# psoc4100sp register map
Vendor: Cypress Semiconductor; Series: PSoC4100Sp; File version: 1.0
CPU: CM0PLUS r0p1, little endian, no MPU, no FPU, VTOR, 2 interrupt priority bits
Registers are 32-bit, read-write, reset 0x0 unless marked. A register's access mark holds for its fields unless they carry their own. Offsets are from the block's base; [hi:lo] are bit positions; lines under a group give offsets from that group; {n}, {i} and the like mark numbered series.

## DMAC — DataWire/DMA Controller
Base 0x40101000
0x00 CTL — Control register
  [31] ENABLED — 0': IP is disabled. Non-retainable MMIO registers and logic functionality are reset (retainable MMIO registers are NOT reset): - INTR register is set to '0'. - DW/DMA functionality is aborted. - DW/DMA controller input/pending triggers are de-activated. - DW/DMA controller output triggers are de-activated. Disabling the IP has the same effect as an active 'rst_sys_act_n' reset in DeepSleep power mode. To prevent a loss of active (pending) DW/DMA triggers when disabling the IP or when transitioning from Active to DeepSleep power mode, the STATUS.ACTIVE and STATUS_CH_ACTIVE.CH fields can be used. Note that most MMIO registers are retainable, and a transition from DeepSleep to Active/Sleep power modes makes the DW/DMA controller operational, and ready to react to DW/DMA input triggers that are activated after the transition. Triggers are Active/Sleep functionality. '1': IP is enabled.
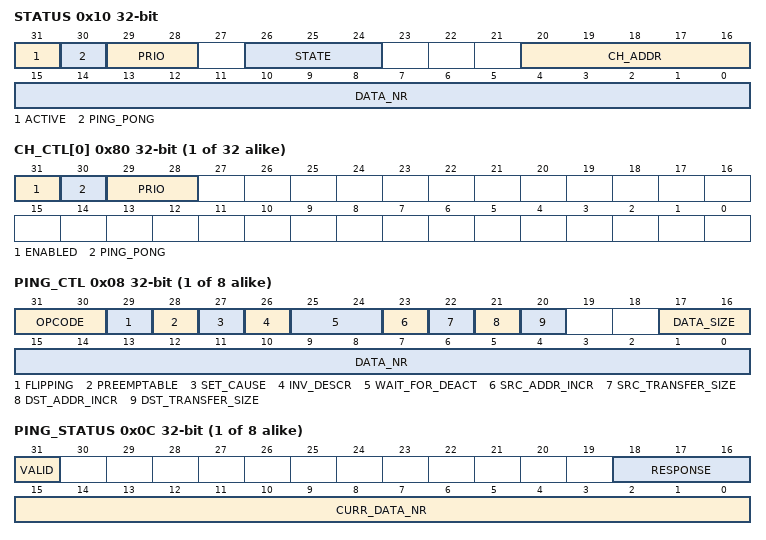
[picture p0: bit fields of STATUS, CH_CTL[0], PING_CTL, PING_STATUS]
0x10 STATUS ro (reset mask 0x87000000)
  [31] ACTIVE — Specifies if there is a currently active (pending) channel in the data transfer engine: '0': no currently active channel. '1': currently active channel.
  [30] PING_PONG — Specifies whether the PING descriptor ('0') or PONG descriptor ('1') of the channel is currently in use.
  [29:28] PRIO — Specifies the priority of the currently active channel.
  [26:24] STATE — State of the data transfer engine. '0': DEFAULT state. '1': Loading descriptor (SRC, DST, CONTROL and STATUS words). '2': Loading data element from source location. '3': Storing data element to destination location. '4': Storing descriptor (STATUS word). '5': Wait for trigger de-activation. '6': Storing descriptor with error response (STATUS word).
  [20:16] CH_ADDR — Specifies the channel number of the currently active channel. E.g. if we have 32 channels, the channel number address with CH_ADDR_WIDTH is LOG2 (32) = 5, and this field is a 5-bit field. If channel 7 is active, STATUS.ACTIVE is '1' and STATUS.CH_ADDR is '7'.
  [15:0] DATA_NR — Specifies the index of the currently active data transfer. This value increases from '0' to CONTROL.DATA_NR.
0x14 STATUS_SRC_ADDR ro reset not defined — Source address status register
  [31:0] ADDR — Base address or current address of source location of currently active channel. The specific address information is cycle dependent. This is field is provided for debug purposes. Functionally, no assumption should be made on whether the base or current address is provided. The specifics of the currently active channel are available through STATUS. Note while reading the STATUS, STATUS_SRC and STATUS_DST registers, the transfer engine may have moved from one active channel to another.
0x18 STATUS_DST_ADDR ro reset not defined — Destination address register
  [31:0] ADDR — Base address or current address of destination location of currently active channel. The specific address information is cycle dependent. This is field is provided for debug purposes. Functionally, no assumption should be made on whether the base or current address is provided. The specifics of the currently active channel are available through STATUS. Note while reading the STATUS, STATUS_SRC and STATUS_DST registers, the transfer engine may have moved from one active channel to another.
0x1C STATUS_CH_ACT ro — Channel activation status register
  [31:0] CH — Channel activation status. Bit i is associated to channel i, with i = 0, ..., CH_NR-1. Software reads this field to get information on all actively pending channels (either in pending or in the data transfer engine).
{0x80+4i} CH_CTL[{i}] (i=0..31) — Channel control register
  [31] ENABLED — '0': channel disabled. The channel's trigger is ignored and the channel cannot be activated. If the activated channel is disabled, the data transfer(s) are aborted. '1': channel enabled. Software sets this field to '1' to enable a specific channel. Hardware sets this field to '0' on erroneous channel behavior (the specific error is specified by STATUS.RESP in the channel's descriptor structure).
  [30] PING_PONG — Each channel has two descriptor structures for double buffering purposes. As the controller operates on one structure, the main CPU can operate on the other structure. The descriptor structures are identified as PING ('0') and PONG ('1'). This field identifies the descriptor structure that is currently in use by the controller. Software sets this field to the desired descriptor structure. Hardware inverts the field value on the completion of a descriptor structure when CONTROL.FLIPPING of the current descriptor structure is set to '1'. Each channel has two descriptor structures for double buffering purposes. As the controller operates on one structure, the main CPU can operate on the other structure. The descriptor structures are identified as PING ('0') and PONG ('1'). This field identifies the descriptor structure that is currently in use by the controller.
  [29:28] PRIO — Channel priority, with '0' representing the highest priority and '3' representing the lowest priority. Priority decoding uses the channel priority to determine the highest priority activated channel. If multiple activated channels have the same highest priority, the channel with the lowest index i, is considered the highest priority activated channel.
0x7F0 INTR — Interrupt register
  [31:0] CH — Set to '1', when event is detected. Write INTR field with '1', to clear bit. Write INTR_SET field with '1', to set bit.
0x7F4 INTR_SET — Interrupt set register
  [31:0] CH — Write INTR_SET field with '1' to set corresponding INTR field (a write of '0' has no effect).
0x7F8 INTR_MASK — Interrupt mask register
  [31:0] CH — Mask for corresponding field in INTR register.
0x7FC INTR_MASKED ro — Interrupt masked register
  [31:0] CH — Logical and of corresponding request and mask fields.
{0x800+0x20*i} DESCR[{i}] (i=0..7) group — Descriptors
  0x00 PING_SRC reset not defined — Ping source address
    [31:0] ADDR — Base address of source location. The effective source location is calculated by adding on offset (derived from PING.STATUS.CURR_DATA_NR) to this base address.
  0x04 PING_DST reset not defined — Ping destination address
    [31:0] ADDR — Base address of destination location. The effective destination location is calculated by adding on offset (derived from PING.STATUS.CURR_DATA_NR) to this base address.
  0x08 PING_CTL reset not defined — Ping control word
    [31:30] OPCODE — Specifies the specific data transfer (only when the VALID bit of the descriptor's STATUS word is '1'): '0': A single trigger initiates a single data element transfer (DW mode). This opcode specifies a transfer of a single data element. The current descriptor is completed when the amount of transferred single data elements equals the programmed buffer size (DATA_NR+1). '1': A single trigger initiates a single descriptor transfer (DMA mode). This opcode specifies a transfer of DATA_NR+1 data elements as specified by the current descriptor structure. The current descriptor is completed when its data transfer is completed. '2': A single trigger initiates a descriptor list transfer (DMA mode). This opcode specifies a transfer of DATA_NR+1 data elements as specified by the current descriptor structure and by successive valid descriptors. The current descriptor is completed when its data transfer is completed. This OPCODE relies on FLIPPING to be set to '1', such that the CHi_CTL.PING_PONG field is flipped/inverted and the successive descriptor is used. This continues for as long as the successive descriptor is valid. Note that as the HW is using the PING/PONG descriptor, the SW can prepare the alternate PONG/PING descriptor. The interrupt mechanism is used by HW to convey to the SW that the current descriptor is completed (and can be prepared for a successive transfer). After completerion of the opcode (and waiting for de-activation, the channel's output trigger is activated).
    [29] FLIPPING — '1': On completion of the current descriptor structure, the current descriptor identifier CHi_CTL.PING_PONG is flipped/inverted. In DMA mode, descriptor list transfer, flipping of the current descriptor identifier can be used to construct a linked list of descriptor structures.
    [28] PREEMPTABLE — '1': Transfer is preemptable. In DMA mode (OPCODE is '1' or '2'), multi data element transfers are constructed out of multiple single data element load (from the source location) and store (to the destination location) sequences. This field allows higher priority activated channels to preempt the current transfer in between these atomic (load, store) sequences. Preemption will NOT deactivate the current channel. As a result, after completion of a higher priority activated channel, the current channel is rescheduled.
    [27] SET_CAUSE — '1': On completion of the current descriptor structure, the interrupt cause field of the channel is set to '1' (INTR.CH[i]).
    [26] INV_DESCR — '1': On completion of the current descriptor structure, the VALID bit of the descriptor's STATUS word is set to '0'.
    [25:24] WAIT_FOR_DEACT — Specifies whether the data transfer engine should wait for the channel to be deactivated; i.e. the selected system trigger is not active. This field is used to synchronize the controller's data transfer(s) with the agent that generated the trigger. This field is ONLY used at the completion of an opcode. E.g., a FIFO indicates that it is empty and it needs a new data sample. The agent removes the trigger ONLY when the data sample has been written by the transfer engine AND received by the agent. Furthermore, the agent's trigger may be delayed by a few cycles before it reaches the DW/DMA controller. This field is used for level sensitive trigger, which reflect state (pulse sensitive triggers should have this field set to '0'). The wait cycles incurred by this field reduce DW/DMA controller performance. '0': Do not wait for de-activation (for pulse sensitive triggers). '1': Wait for up to 4 cycles. '2': Wait for up to 8 cycles. '3': Wait indefinitely. This option may result in DW/DMA controller lockup if the system trigger is not de-activated by the source agent.
    [23] SRC_ADDR_INCR — Specifies whether the source location address is incremented by the SRC_TRANSFER_SIZE after each single data element transfer or not. '0': No increment, typically used for receive (RX) FIFO structures. '1': Increment, typically used for memory structures.
    [22] SRC_TRANSFER_SIZE — Specifies the bus transfer size to the source location: '0': As specified by DATA_SIZE. '1': Word (32 bits). Distinguishing bus transfer size from data element size allows for source components with data elements that are smaller than their 32-bit bus interface width. E.g., an ADC source has a 32-bit bus transfer size, but only provides a 16-bit data element.
    [21] DST_ADDR_INCR — Specifies whether the destination location address is incremented by the DST_TRANSFER_SIZE after each single data element transfer or not. '0' : No increment, typically used for transmit (TX) FIFO structures. '1': Increment, typically used for memory structures.
    [20] DST_TRANSFER_SIZE — Specifies the bus transfer size to the destination location: '0': As specified by DATA_SIZE. '1': Word (32 bits). Distinguishing bus transfer size from data element size allows for destination components with data elements that are smaller than their 32-bit bus interface width. E.g., a DAC destination has a 32-bit bus transfer size, but only requires a 16-bit data element.
    [17:16] DATA_SIZE — Specifies the data element size: '0': Byte (8 bits). '1': Halfword (16 bits). '2': Word (32 bits). DATA_SIZE, SRC_TRANSFER_SIZE and DST_TRANSFER_SIZE together determine how data elements are transferred. The following are the 9 legal settings: - DATA is 8 bit, SRC is 8 bit, DST is 8 bit - DATA is 8 bit, SRC is 32 bit (higher 24 bits are dropped), DST is 8 bit - DATA is 8 bit, SRC is 8 bit, DST is 32 bit (higher 24 bits are made '0') - DATA is 8 bit, SRC is 32 bit (higher 24 bits are dropped), DST is 32 bit (higher 24 bits are made '0') - DATA is 16 bit, SRC is 16 bit, DST is 16 bit - DATA is 16 bit, SRC is 32 bit (higher 16 bits are dropped), DST is 16 bit - DATA is 16 bit, SRC is 16 bit, DST is 32 bit (higher 16 bits are made '0') - DATA is 16 bit, SRC is 32 bit (higher 16 bits are dropped), DST is 32 bit (higher 16 bits are made '0') - DATA is 32 bit, SRC is 32 bit, DST is 32 bit
    [15:0] DATA_NR — Number of data elements that are transferred by a single descriptor. In DW mode (OPCODE is '0') each trigger initiates the transfer of a single data element. This field specifies the source and/or destination buffer size in data elements: buffer size = DATA_NR+1. The buffer is typically associated to a memory structure. In DMA mode (OPCODE is '1' or '2') each trigger initiates the transfer of DATA_NR+1 data elements.
  0x0C PING_STATUS reset not defined — Ping status word
    [31] VALID — '0': Invalid, cannot be used for a data transfer. An attempt to use this descriptor for a data transfer will result in an INVALID_DESCR response code (and the interrupt cause bit is set to '1'). '1': Valid. Hardware set this field to '0' when a descriptor is done, but only if CONTROL.INV_DESCR is '1'. Software sets this field to '1' when a descriptor is initialized.
    [18:16] RESPONSE — Response code (the first two codes NO_ERROR and DONE are the result of normal behavior, the other codes are the result of erroneous behavior). '0'/NO_ERROR: No error. Setting this response does NOT set the interrupt cause bit to '1'. STATUS.VALID is NOT affected. CHi_CTL.ENABLED is NOT affected. CHi_CTL.PING_PONG is not updated. This response is used for an unused or not completed descriptor. Software should set the RESPONSE field to '0'/NO_ERROR during descriptor initialization. '1'/DONE: Descriptor is done (without errors). Setting this response sets the interrupt cause bit to '1' if CONTROL.SET_CAUSE is '1'. STATUS.VALID is set to '0' if CONTROL.INV_DESCR is '1'. CHi_CTL.ENABLED is NOT affected. CHi_CTL.PING_PONG is updated if CONTROL.FLIPPING is '1'. '2'/SRC_BUS_ERROR: Bus error while loading data from the source location. Setting this response sets the interrupt cause bit to '1'. STATUS.VALID is set '0'. CHi_CTL.ENABLED is set to '0'. CHi_CTL.PING_PONG is not updated (it identifies the descriptor that caused the error). '3'/DST_BUS_ERROR: Bus error while storing data to the destination location. Setting this response sets the interrupt cause bit to '1'. STATUS.VALID is set '0'. CHi_CTL.ENABLED is set to '0'. CHi_CTL.PING_PONG is not updated (it identifies the descriptor that caused the error). '4'/SRC_MISAL: Misalignment of source address. This occurs on a 16-bit bus transfer that is not 2-byte aligned or on a 32-bit bus transfer that is not 4-byte aligned. Setting this response sets the interrupt cause bit to '1'. STATUS.VALID is set '0'. CHi_CTL.ENABLED is set to '0'. CHi_CTL.PING_PONG is not updated (it identifies the descriptor that caused the error). '5'/DST_MISAL: Misalignment of destination address. This occurs on a 16-bit bus transfer that is not 2-byte aligned or on a 32-bit bus transfer that is not 4-byte aligned. Setting this response sets the interrupt cause bit to '1'. STATUS.VALID is set '0'. CHi_CTL.ENABLED is set to '0'. CHi_CTL.PING_PONG is not updated (it identifies the descriptor that caused the error). '6'/INVALID_DESCR: Invalid descriptor (STATUS.VALID is '0'). This occurs when an activated channel has an invalid descriptor. CHi_CTL.ENABLED is set to '0'. CHi_CTL.PING_PONG is not updated (it identifies the descriptor that caused the error).
    [15:0] CURR_DATA_NR — Specifies the index of the current data transfer. This value increases from 0 to CONTROL.DATA_NR. HW sets this field: - When a descriptor is done (RESPONSE is DONE), the field is set to '0' when PING_CTL.INV_DESCR is '0' and the field is set to PING_CTL.DATA_NR when PING_CTL.INV_DESCR is '1'. - When a descriptor is not done (RESPONSE is NO_ERROR), the field reflects the progress of a data transfer. - In case of erroneous behavior (RESPONSE is neither DONE or NO_ERROR), the field is not updated, but keeps its value to ease debugging. HW only modifies this field for an active descriptor (STATUS.VALID to be '1'). At descriptor initialization, SW should set this field to '0'. This field allows software to read the progress of the data transfer. Note that SRC.ADDR and DST.ADDR represent base addresses and are not modified during data transfer. However, STATUS.CURR_DATA_NR is modified during data transfer and provides an offset wrt. the base addresses.
  0x10 PONG_SRC reset not defined — Pong source address
    [31:0] ADDR — See description of PING_SRC.
  0x14 PONG_DST reset not defined — Pong destination address
    [31:0] ADDR — See description of PING_DST.
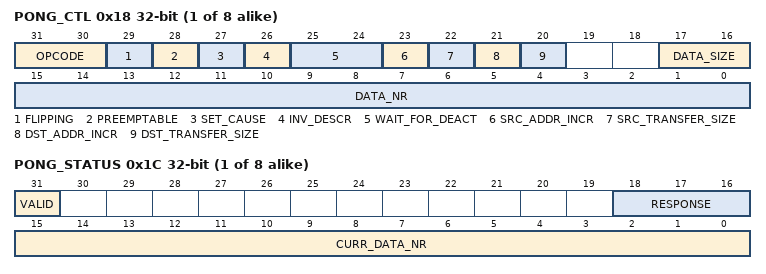
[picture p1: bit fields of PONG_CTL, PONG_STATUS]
  0x18 PONG_CTL reset not defined — Pong control word
    [31:30] OPCODE — See description of PING_CTL.
    [29] FLIPPING — See description of PING_CTL.
    [28] PREEMPTABLE — See description of PING_CTL.
    [27] SET_CAUSE — See description of PING_CTL.
    [26] INV_DESCR — See description of PING_CTL.
    [25:24] WAIT_FOR_DEACT — See description of PING_CTL.
    [23] SRC_ADDR_INCR — See description of PING_CTL.
    [22] SRC_TRANSFER_SIZE — See description of PING_CTL.
    [21] DST_ADDR_INCR — See description of PING_CTL.
    [20] DST_TRANSFER_SIZE — See description of PING_CTL.
    [17:16] DATA_SIZE — See description of PING_CTL.
    [15:0] DATA_NR — See description of PING_CTL.
  0x1C PONG_STATUS reset not defined — Pong status word
    [31] VALID — See description of PING_STATUS.
    [18:16] RESPONSE — See description of PING_STATUS.
    [15:0] CURR_DATA_NR — See description of PING_STATUS.

## Notices in the file
Copyright 2016-2020 Cypress Semiconductor Corporation
Licensed under the Apache License, Version 2.0 (the "License");
you may not use this file except in compliance with the License.
You may obtain a copy of the License at
http://www.apache.org/licenses/LICENSE-2.0
Unless required by applicable law or agreed to in writing, software
distributed under the License is distributed on an "AS IS" BASIS,
WITHOUT WARRANTIES OR CONDITIONS OF ANY KIND, either express or implied.
See the License for the specific language governing permissions and
limitations under the License.
